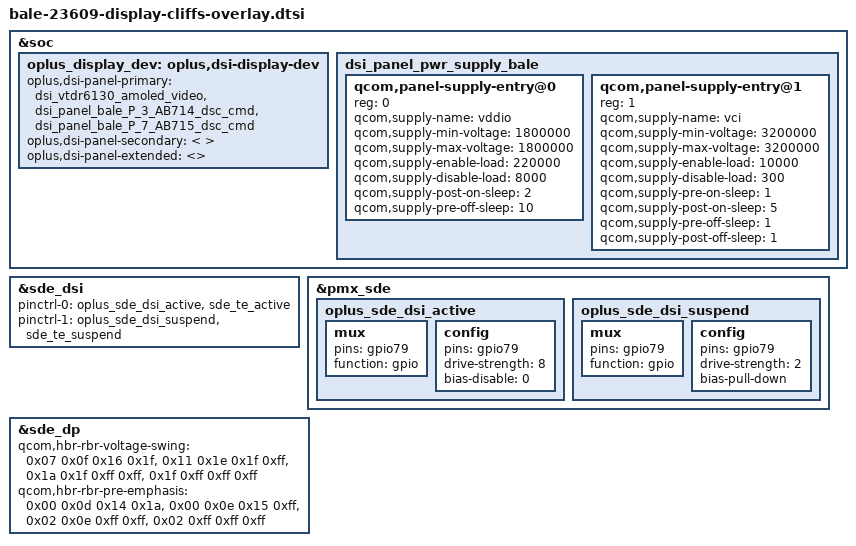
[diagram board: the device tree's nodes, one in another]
#include "panel/dsi-panel-bale-P-3-AB714-dsc-cmd.dtsi"
#include "panel/dsi-panel-bale-P-7-AB715-dsc-cmd.dtsi"
&soc {
	oplus_display_dev: oplus,dsi-display-dev {
		oplus,dsi-panel-primary = <
			&dsi_vtdr6130_amoled_video
		     &dsi_panel_bale_P_3_AB714_dsc_cmd
			&dsi_panel_bale_P_7_AB715_dsc_cmd
		>;
		oplus,dsi-panel-secondary = <
		>;
		oplus,dsi-panel-extended = <>;
	};


	dsi_panel_pwr_supply_bale: dsi_panel_pwr_supply_bale {
                #address-cells = <1>;
                #size-cells = <0>;

                qcom,panel-supply-entry@0 {
                        reg = <0>;
                        qcom,supply-name = "vddio";
                        qcom,supply-min-voltage = <1800000>;
                        qcom,supply-max-voltage = <1800000>;
                        qcom,supply-enable-load = <220000>;
                        qcom,supply-disable-load = <8000>;
                        qcom,supply-post-on-sleep = <2>;
                        qcom,supply-pre-off-sleep = <10>;
                };

                qcom,panel-supply-entry@1 {
                        reg = <1>;
                        qcom,supply-name = "vci";
                        qcom,supply-min-voltage = <3200000>;
                        qcom,supply-max-voltage = <3200000>;
                        qcom,supply-enable-load = <10000>;
                        qcom,supply-disable-load = <300>;
                        qcom,supply-pre-on-sleep = <1>;
                        qcom,supply-post-on-sleep = <5>;
                        qcom,supply-pre-off-sleep = <1>;
                        qcom,supply-post-off-sleep = <1>;
                };
        };
};

&sde_dsi {
	pinctrl-names = "panel_active", "panel_suspend";
	pinctrl-0 = <&oplus_sde_dsi_active &sde_te_active>;
	pinctrl-1 = <&oplus_sde_dsi_suspend &sde_te_suspend>;
};

&pmx_sde {
	oplus_sde_dsi_active: oplus_sde_dsi_active {
		mux {
			pins = "gpio79";
			function = "gpio";
		};

		config {
			pins = "gpio79";
			drive-strength = <8>;   /* 8 mA */
			bias-disable = <0>;   /* no pull */
		};
	};

	oplus_sde_dsi_suspend: oplus_sde_dsi_suspend {
		mux {
			pins = "gpio79";
			function = "gpio";
		};

		config {
			pins = "gpio79";
			drive-strength = <2>;   /* 2 mA */
			bias-pull-down;         /* PULL DOWN */
		};
	};
};


&sde_dp {
	qcom,hbr-rbr-voltage-swing = <0x07 0x0f 0x16 0x1f>,
				<0x11 0x1e 0x1f 0xff>,
				<0x1a 0x1f 0xff 0xff>,
				<0x1f 0xff 0xff 0xff>;
	qcom,hbr-rbr-pre-emphasis = <0x00 0x0d 0x14 0x1a>,
				<0x00 0x0e 0x15 0xff>,
				<0x02 0x0e 0xff 0xff>,
				<0x02 0xff 0xff 0xff>;
};
